# ESP32-S3 register map
Vendor: ESPRESSIF SYSTEMS (SHANGHAI) CO., LTD.; Series: ESP32 S-Series; File version: 22
CPU: Xtensa LX7 r0p0, little endian, no MPU, FPU, 0 interrupt priority bits
Address unit: 32 bits
Registers are 32-bit, read-write, reset 0x0 unless marked. A register's access mark holds for its fields unless they carry their own. Offsets are from the block's base; [hi:lo] are bit positions.

## UART0 — UART (Universal Asynchronous Receiver-Transmitter) Controller 0
Base 0x60000000
Same registers: UART1 0x60010000, UART2 0x6002E000
0x00 FIFO ro — FIFO data register
  [7:0] RXFIFO_RD_BYTE — UART 0 accesses FIFO via this register.
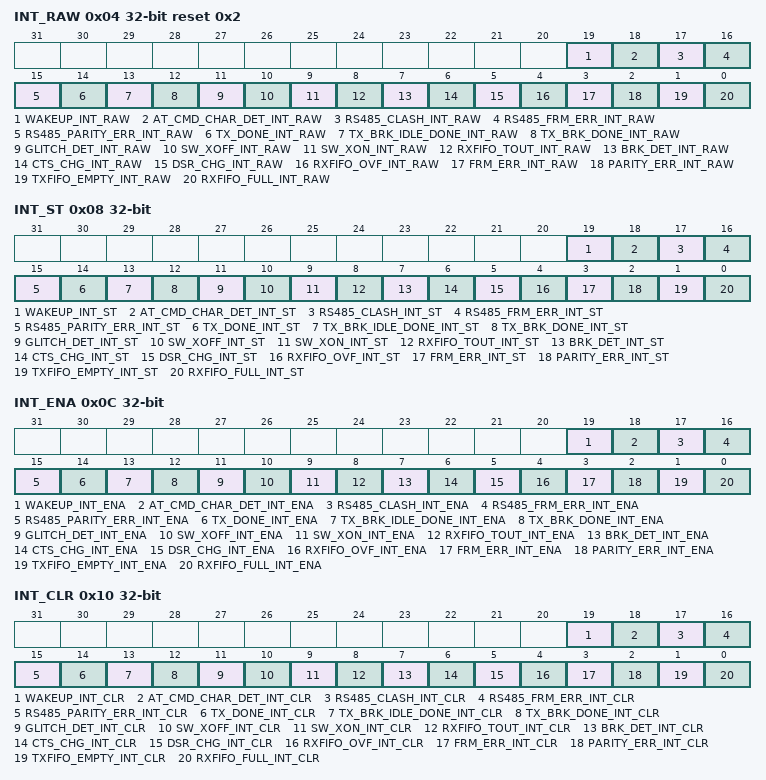
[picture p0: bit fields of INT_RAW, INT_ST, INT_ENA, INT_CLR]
0x04 INT_RAW reset 0x2 — Raw interrupt status
  [19] WAKEUP_INT_RAW — This interrupt raw bit turns to high level when input rxd edge changes more times than what reg_active_threshold specifies in light sleeping mode.
  [18] AT_CMD_CHAR_DET_INT_RAW — This interrupt raw bit turns to high level when receiver detects the configured at_cmd char.
  [17] RS485_CLASH_INT_RAW — This interrupt raw bit turns to high level when detects a clash between transmitter and receiver in rs485 mode.
  [16] RS485_FRM_ERR_INT_RAW — This interrupt raw bit turns to high level when receiver detects a data frame error from the echo of transmitter in rs485 mode.
  [15] RS485_PARITY_ERR_INT_RAW — This interrupt raw bit turns to high level when receiver detects a parity error from the echo of transmitter in rs485 mode.
  [14] TX_DONE_INT_RAW — This interrupt raw bit turns to high level when transmitter has send out all data in FIFO.
  [13] TX_BRK_IDLE_DONE_INT_RAW — This interrupt raw bit turns to high level when transmitter has kept the shortest duration after sending the last data.
  [12] TX_BRK_DONE_INT_RAW — This interrupt raw bit turns to high level when transmitter completes sending NULL characters, after all data in Tx-FIFO are sent.
  [11] GLITCH_DET_INT_RAW — This interrupt raw bit turns to high level when receiver detects a glitch in the middle of a start bit.
  [10] SW_XOFF_INT_RAW — This interrupt raw bit turns to high level when receiver receives Xoff char when uart_sw_flow_con_en is set to 1.
  [9] SW_XON_INT_RAW — This interrupt raw bit turns to high level when receiver recevies Xon char when uart_sw_flow_con_en is set to 1.
  [8] RXFIFO_TOUT_INT_RAW — This interrupt raw bit turns to high level when receiver takes more time than rx_tout_thrhd to receive a byte.
  [7] BRK_DET_INT_RAW — This interrupt raw bit turns to high level when receiver detects a 0 after the stop bit.
  [6] CTS_CHG_INT_RAW — This interrupt raw bit turns to high level when receiver detects the edge change of CTSn signal.
  [5] DSR_CHG_INT_RAW — This interrupt raw bit turns to high level when receiver detects the edge change of DSRn signal.
  [4] RXFIFO_OVF_INT_RAW — This interrupt raw bit turns to high level when receiver receives more data than the FIFO can store.
  [3] FRM_ERR_INT_RAW — This interrupt raw bit turns to high level when receiver detects a data frame error .
  [2] PARITY_ERR_INT_RAW — This interrupt raw bit turns to high level when receiver detects a parity error in the data.
  [1] TXFIFO_EMPTY_INT_RAW — This interrupt raw bit turns to high level when the amount of data in Tx-FIFO is less than what txfifo_empty_thrhd specifies .
  [0] RXFIFO_FULL_INT_RAW — This interrupt raw bit turns to high level when receiver receives more data than what rxfifo_full_thrhd specifies.
0x08 INT_ST ro — Masked interrupt status
  [19] WAKEUP_INT_ST — This is the status bit for uart_wakeup_int_raw when uart_wakeup_int_ena is set to 1.
  [18] AT_CMD_CHAR_DET_INT_ST — This is the status bit for at_cmd_det_int_raw when at_cmd_char_det_int_ena is set to 1.
  [17] RS485_CLASH_INT_ST — This is the status bit for rs485_clash_int_raw when rs485_clash_int_ena is set to 1.
  [16] RS485_FRM_ERR_INT_ST — This is the status bit for rs485_frm_err_int_raw when rs485_fm_err_int_ena is set to 1.
  [15] RS485_PARITY_ERR_INT_ST — This is the status bit for rs485_parity_err_int_raw when rs485_parity_int_ena is set to 1.
  [14] TX_DONE_INT_ST — This is the status bit for tx_done_int_raw when tx_done_int_ena is set to 1.
  [13] TX_BRK_IDLE_DONE_INT_ST — This is the stauts bit for tx_brk_idle_done_int_raw when tx_brk_idle_done_int_ena is set to 1.
  [12] TX_BRK_DONE_INT_ST — This is the status bit for tx_brk_done_int_raw when tx_brk_done_int_ena is set to 1.
  [11] GLITCH_DET_INT_ST — This is the status bit for glitch_det_int_raw when glitch_det_int_ena is set to 1.
  [10] SW_XOFF_INT_ST — This is the status bit for sw_xoff_int_raw when sw_xoff_int_ena is set to 1.
  [9] SW_XON_INT_ST — This is the status bit for sw_xon_int_raw when sw_xon_int_ena is set to 1.
  [8] RXFIFO_TOUT_INT_ST — This is the status bit for rxfifo_tout_int_raw when rxfifo_tout_int_ena is set to 1.
  [7] BRK_DET_INT_ST — This is the status bit for brk_det_int_raw when brk_det_int_ena is set to 1.
  [6] CTS_CHG_INT_ST — This is the status bit for cts_chg_int_raw when cts_chg_int_ena is set to 1.
  [5] DSR_CHG_INT_ST — This is the status bit for dsr_chg_int_raw when dsr_chg_int_ena is set to 1.
  [4] RXFIFO_OVF_INT_ST — This is the status bit for rxfifo_ovf_int_raw when rxfifo_ovf_int_ena is set to 1.
  [3] FRM_ERR_INT_ST — This is the status bit for frm_err_int_raw when frm_err_int_ena is set to 1.
  [2] PARITY_ERR_INT_ST — This is the status bit for parity_err_int_raw when parity_err_int_ena is set to 1.
  [1] TXFIFO_EMPTY_INT_ST — This is the status bit for txfifo_empty_int_raw when txfifo_empty_int_ena is set to 1.
  [0] RXFIFO_FULL_INT_ST — This is the status bit for rxfifo_full_int_raw when rxfifo_full_int_ena is set to 1.
0x0C INT_ENA — Interrupt enable bits
  [19] WAKEUP_INT_ENA — This is the enable bit for uart_wakeup_int_st register.
  [18] AT_CMD_CHAR_DET_INT_ENA — This is the enable bit for at_cmd_char_det_int_st register.
  [17] RS485_CLASH_INT_ENA — This is the enable bit for rs485_clash_int_st register.
  [16] RS485_FRM_ERR_INT_ENA — This is the enable bit for rs485_parity_err_int_st register.
  [15] RS485_PARITY_ERR_INT_ENA — This is the enable bit for rs485_parity_err_int_st register.
  [14] TX_DONE_INT_ENA — This is the enable bit for tx_done_int_st register.
  [13] TX_BRK_IDLE_DONE_INT_ENA — This is the enable bit for tx_brk_idle_done_int_st register.
  [12] TX_BRK_DONE_INT_ENA — This is the enable bit for tx_brk_done_int_st register.
  [11] GLITCH_DET_INT_ENA — This is the enable bit for glitch_det_int_st register.
  [10] SW_XOFF_INT_ENA — This is the enable bit for sw_xoff_int_st register.
  [9] SW_XON_INT_ENA — This is the enable bit for sw_xon_int_st register.
  [8] RXFIFO_TOUT_INT_ENA — This is the enable bit for rxfifo_tout_int_st register.
  [7] BRK_DET_INT_ENA — This is the enable bit for brk_det_int_st register.
  [6] CTS_CHG_INT_ENA — This is the enable bit for cts_chg_int_st register.
  [5] DSR_CHG_INT_ENA — This is the enable bit for dsr_chg_int_st register.
  [4] RXFIFO_OVF_INT_ENA — This is the enable bit for rxfifo_ovf_int_st register.
  [3] FRM_ERR_INT_ENA — This is the enable bit for frm_err_int_st register.
  [2] PARITY_ERR_INT_ENA — This is the enable bit for parity_err_int_st register.
  [1] TXFIFO_EMPTY_INT_ENA — This is the enable bit for txfifo_empty_int_st register.
  [0] RXFIFO_FULL_INT_ENA — This is the enable bit for rxfifo_full_int_st register.
0x10 INT_CLR wo — Interrupt clear bits
  [19] WAKEUP_INT_CLR — Set this bit to clear the uart_wakeup_int_raw interrupt.
  [18] AT_CMD_CHAR_DET_INT_CLR — Set this bit to clear the at_cmd_char_det_int_raw interrupt.
  [17] RS485_CLASH_INT_CLR — Set this bit to clear the rs485_clash_int_raw interrupt.
  [16] RS485_FRM_ERR_INT_CLR — Set this bit to clear the rs485_frm_err_int_raw interrupt.
  [15] RS485_PARITY_ERR_INT_CLR — Set this bit to clear the rs485_parity_err_int_raw interrupt.
  [14] TX_DONE_INT_CLR — Set this bit to clear the tx_done_int_raw interrupt.
  [13] TX_BRK_IDLE_DONE_INT_CLR — Set this bit to clear the tx_brk_idle_done_int_raw interrupt.
  [12] TX_BRK_DONE_INT_CLR — Set this bit to clear the tx_brk_done_int_raw interrupt..
  [11] GLITCH_DET_INT_CLR — Set this bit to clear the glitch_det_int_raw interrupt.
  [10] SW_XOFF_INT_CLR — Set this bit to clear the sw_xoff_int_raw interrupt.
  [9] SW_XON_INT_CLR — Set this bit to clear the sw_xon_int_raw interrupt.
  [8] RXFIFO_TOUT_INT_CLR — Set this bit to clear the rxfifo_tout_int_raw interrupt.
  [7] BRK_DET_INT_CLR — Set this bit to clear the brk_det_int_raw interrupt.
  [6] CTS_CHG_INT_CLR — Set this bit to clear the cts_chg_int_raw interrupt.
  [5] DSR_CHG_INT_CLR — Set this bit to clear the dsr_chg_int_raw interrupt.
  [4] RXFIFO_OVF_INT_CLR — Set this bit to clear rxfifo_ovf_int_raw interrupt.
  [3] FRM_ERR_INT_CLR — Set this bit to clear frm_err_int_raw interrupt.
  [2] PARITY_ERR_INT_CLR — Set this bit to clear parity_err_int_raw interrupt.
  [1] TXFIFO_EMPTY_INT_CLR — Set this bit to clear txfifo_empty_int_raw interrupt.
  [0] RXFIFO_FULL_INT_CLR — Set this bit to clear the rxfifo_full_int_raw interrupt.
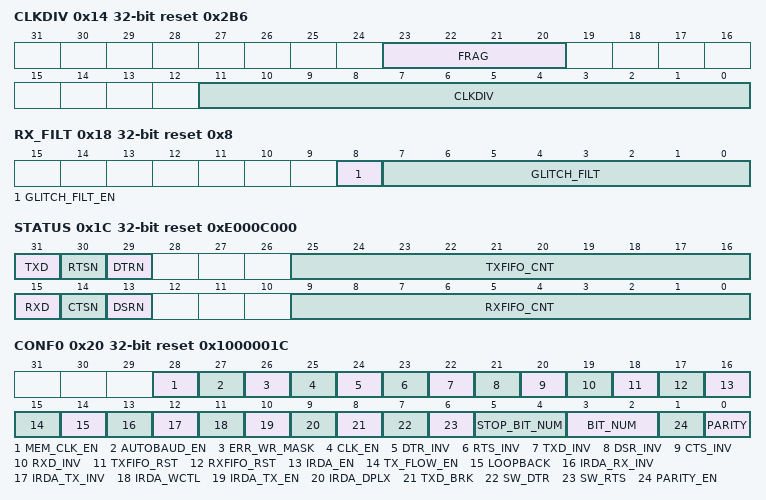
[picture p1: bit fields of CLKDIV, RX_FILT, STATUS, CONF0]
0x14 CLKDIV reset 0x2B6 — Clock divider configuration
  [23:20] FRAG — The decimal part of the frequency divider factor.
  [11:0] CLKDIV — The integral part of the frequency divider factor.
0x18 RX_FILT reset 0x8 — Rx Filter configuration
  [8] GLITCH_FILT_EN — Set this bit to enable Rx signal filter.
  [7:0] GLITCH_FILT — when input pulse width is lower than this value, the pulse is ignored.
0x1C STATUS ro reset 0xE000C000 — UART status register
  [31] TXD — This bit represents the level of the internal uart txd signal.
  [30] RTSN — This bit represents the level of the internal uart rts signal.
  [29] DTRN — This bit represents the level of the internal uart dtr signal.
  [25:16] TXFIFO_CNT — Stores the byte number of data in Tx-FIFO.
  [15] RXD — This register represent the level value of the internal uart rxd signal.
  [14] CTSN — This register represent the level value of the internal uart cts signal.
  [13] DSRN — The register represent the level value of the internal uart dsr signal.
  [9:0] RXFIFO_CNT — Stores the byte number of valid data in Rx-FIFO.
0x20 CONF0 reset 0x1000001C — a
  [28] MEM_CLK_EN — UART memory clock gate enable signal.
  [27] AUTOBAUD_EN — This is the enable bit for detecting baudrate.
  [26] ERR_WR_MASK — 1'h1: Receiver stops storing data into FIFO when data is wrong. 1'h0: Receiver stores the data even if the received data is wrong.
  [25] CLK_EN — 1'h1: Force clock on for register. 1'h0: Support clock only when application writes registers.
  [24] DTR_INV — Set this bit to inverse the level value of uart dtr signal.
  [23] RTS_INV — Set this bit to inverse the level value of uart rts signal.
  [22] TXD_INV — Set this bit to inverse the level value of uart txd signal.
  [21] DSR_INV — Set this bit to inverse the level value of uart dsr signal.
  [20] CTS_INV — Set this bit to inverse the level value of uart cts signal.
  [19] RXD_INV — Set this bit to inverse the level value of uart rxd signal.
  [18] TXFIFO_RST — Set this bit to reset the uart transmit-FIFO.
  [17] RXFIFO_RST — Set this bit to reset the uart receive-FIFO.
  [16] IRDA_EN — Set this bit to enable IrDA protocol.
  [15] TX_FLOW_EN — Set this bit to enable flow control function for transmitter.
  [14] LOOPBACK — Set this bit to enable uart loopback test mode.
  [13] IRDA_RX_INV — Set this bit to invert the level of IrDA receiver.
  [12] IRDA_TX_INV — Set this bit to invert the level of IrDA transmitter.
  [11] IRDA_WCTL — 1'h1: The IrDA transmitter's 11th bit is the same as 10th bit. 1'h0: Set IrDA transmitter's 11th bit to 0.
  [10] IRDA_TX_EN — This is the start enable bit for IrDA transmitter.
  [9] IRDA_DPLX — Set this bit to enable IrDA loopback mode.
  [8] TXD_BRK — Set this bit to enbale transmitter to send NULL when the process of sending data is done.
  [7] SW_DTR — This register is used to configure the software dtr signal which is used in software flow control.
  [6] SW_RTS — This register is used to configure the software rts signal which is used in software flow control.
  [5:4] STOP_BIT_NUM — This register is used to set the length of stop bit.
  [3:2] BIT_NUM — This register is used to set the length of data.
  [1] PARITY_EN — Set this bit to enable uart parity check.
  [0] PARITY — This register is used to configure the parity check mode.
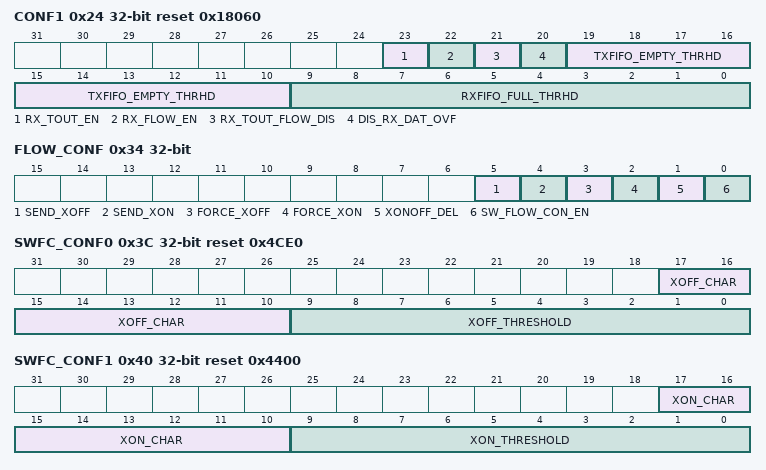
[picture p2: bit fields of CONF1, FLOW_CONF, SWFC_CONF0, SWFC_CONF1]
0x24 CONF1 reset 0x18060 — Configuration register 1
  [23] RX_TOUT_EN — This is the enble bit for uart receiver's timeout function.
  [22] RX_FLOW_EN — This is the flow enable bit for UART receiver.
  [21] RX_TOUT_FLOW_DIS — Set this bit to stop accumulating idle_cnt when hardware flow control works.
  [20] DIS_RX_DAT_OVF — Disable UART Rx data overflow detect.
  [19:10] TXFIFO_EMPTY_THRHD — It will produce txfifo_empty_int interrupt when the data amount in Tx-FIFO is less than this register value.
  [9:0] RXFIFO_FULL_THRHD — It will produce rxfifo_full_int interrupt when receiver receives more data than this register value.
0x28 LOWPULSE ro reset 0xFFF — Autobaud minimum low pulse duration register
  [11:0] MIN_CNT — This register stores the value of the minimum duration time of the low level pulse. It is used in baud rate-detect process.
0x2C HIGHPULSE ro reset 0xFFF — Autobaud minimum high pulse duration register
  [11:0] MIN_CNT — This register stores the value of the maxinum duration time for the high level pulse. It is used in baud rate-detect process.
0x30 RXD_CNT ro — Autobaud edge change count register
  [9:0] RXD_EDGE_CNT — This register stores the count of rxd edge change. It is used in baud rate-detect process.
0x34 FLOW_CONF — Software flow-control configuration
  [5] SEND_XOFF — Set this bit to send Xoff char. It is cleared by hardware automatically.
  [4] SEND_XON — Set this bit to send Xon char. It is cleared by hardware automatically.
  [3] FORCE_XOFF — Set this bit to stop the transmitter from sending data.
  [2] FORCE_XON — Set this bit to enable the transmitter to go on sending data.
  [1] XONOFF_DEL — Set this bit to remove flow control char from the received data.
  [0] SW_FLOW_CON_EN — Set this bit to enable software flow control. It is used with register sw_xon or sw_xoff.
0x38 SLEEP_CONF reset 0xF0 — Sleep-mode configuration
  [9:0] ACTIVE_THRESHOLD — The uart is activated from light sleeping mode when the input rxd edge changes more times than this register value.
0x3C SWFC_CONF0 reset 0x4CE0 — Software flow-control character configuration
  [17:10] XOFF_CHAR — This register stores the Xoff flow control char.
  [9:0] XOFF_THRESHOLD — When the data amount in Rx-FIFO is more than this register value with uart_sw_flow_con_en set to 1, it will send a Xoff char.
0x40 SWFC_CONF1 reset 0x4400 — Software flow-control character configuration
  [17:10] XON_CHAR — This register stores the Xon flow control char.
  [9:0] XON_THRESHOLD — When the data amount in Rx-FIFO is less than this register value with uart_sw_flow_con_en set to 1, it will send a Xon char.
0x44 TXBRK_CONF reset 0xA — Tx Break character configuration
  [7:0] TX_BRK_NUM — This register is used to configure the number of 0 to be sent after the process of sending data is done. It is active when txd_brk is set to 1.
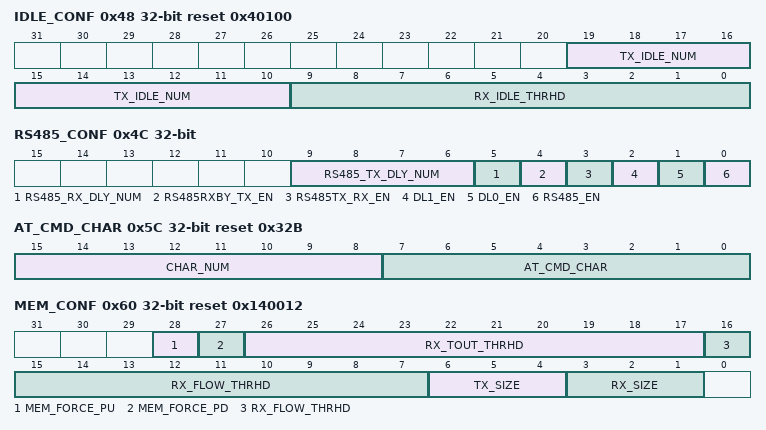
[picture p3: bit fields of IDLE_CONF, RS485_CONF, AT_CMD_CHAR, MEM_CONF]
0x48 IDLE_CONF reset 0x40100 — Frame-end idle configuration
  [19:10] TX_IDLE_NUM — This register is used to configure the duration time between transfers.
  [9:0] RX_IDLE_THRHD — It will produce frame end signal when receiver takes more time to receive one byte data than this register value.
0x4C RS485_CONF — RS485 mode configuration
  [9:6] RS485_TX_DLY_NUM — This register is used to delay the transmitter's internal data signal.
  [5] RS485_RX_DLY_NUM — This register is used to delay the receiver's internal data signal.
  [4] RS485RXBY_TX_EN — 1'h1: enable rs485 transmitter to send data when rs485 receiver line is busy.
  [3] RS485TX_RX_EN — Set this bit to enable receiver could receive data when the transmitter is transmitting data in rs485 mode.
  [2] DL1_EN — Set this bit to delay the stop bit by 1 bit.
  [1] DL0_EN — Set this bit to delay the stop bit by 1 bit.
  [0] RS485_EN — Set this bit to choose the rs485 mode.
0x50 AT_CMD_PRECNT reset 0x901 — Pre-sequence timing configuration
  [15:0] PRE_IDLE_NUM — This register is used to configure the idle duration time before the first at_cmd is received by receiver.
0x54 AT_CMD_POSTCNT reset 0x901 — Post-sequence timing configuration
  [15:0] POST_IDLE_NUM — This register is used to configure the duration time between the last at_cmd and the next data.
0x58 AT_CMD_GAPTOUT reset 0xB — Timeout configuration
  [15:0] RX_GAP_TOUT — This register is used to configure the duration time between the at_cmd chars.
0x5C AT_CMD_CHAR reset 0x32B — AT escape sequence detection configuration
  [15:8] CHAR_NUM — This register is used to configure the num of continuous at_cmd chars received by receiver.
  [7:0] AT_CMD_CHAR — This register is used to configure the content of at_cmd char.
0x60 MEM_CONF reset 0x140012 — UART threshold and allocation configuration
  [28] MEM_FORCE_PU — Set this bit to force power up UART memory.
  [27] MEM_FORCE_PD — Set this bit to force power down UART memory.
  [26:17] RX_TOUT_THRHD — This register is used to configure the threshold time that receiver takes to receive one byte. The rxfifo_tout_int interrupt will be trigger when the receiver takes more time to receive one byte with rx_tout_en set to 1.
  [16:7] RX_FLOW_THRHD — This register is used to configure the maximum amount of data that can be received when hardware flow control works.
  [6:4] TX_SIZE — This register is used to configure the amount of mem allocated for transmit-FIFO. The default number is 128 bytes.
  [3:1] RX_SIZE — This register is used to configure the amount of mem allocated for receive-FIFO. The default number is 128 bytes.
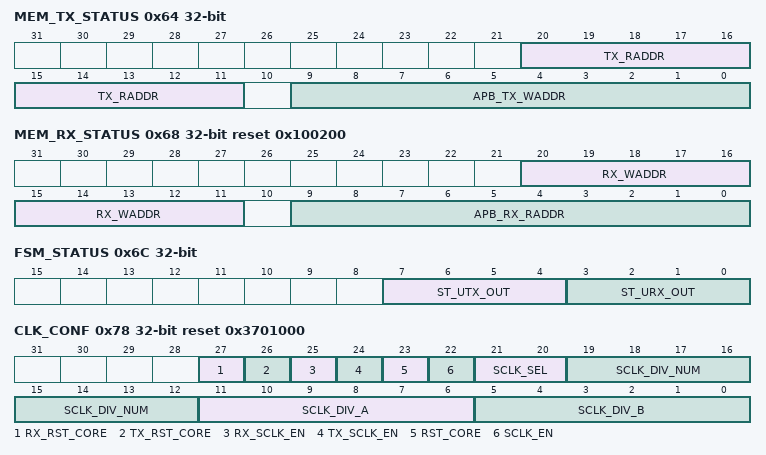
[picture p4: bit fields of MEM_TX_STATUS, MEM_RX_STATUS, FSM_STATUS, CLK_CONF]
0x64 MEM_TX_STATUS ro — Tx-FIFO write and read offset address.
  [20:11] TX_RADDR — This register stores the offset address in Tx-FIFO when Tx-FSM reads data via Tx-FIFO_Ctrl.
  [9:0] APB_TX_WADDR — This register stores the offset address in Tx-FIFO when software writes Tx-FIFO via APB.
0x68 MEM_RX_STATUS ro reset 0x100200 — Rx-FIFO write and read offset address.
  [20:11] RX_WADDR — This register stores the offset address in Rx-FIFO when Rx-FIFO_Ctrl writes Rx-FIFO. UART0 is 10'h200. UART1 is 10'h280. UART2 is 10'h300.
  [9:0] APB_RX_RADDR — This register stores the offset address in RX-FIFO when software reads data from Rx-FIFO via APB. UART0 is 10'h200. UART1 is 10'h280. UART2 is 10'h300.
0x6C FSM_STATUS ro — UART transmit and receive status.
  [7:4] ST_UTX_OUT — This is the status register of transmitter.
  [3:0] ST_URX_OUT — This is the status register of receiver.
0x70 POSPULSE ro reset 0xFFF — Autobaud high pulse register
  [11:0] POSEDGE_MIN_CNT — This register stores the minimal input clock count between two positive edges. It is used in boudrate-detect process.
0x74 NEGPULSE ro reset 0xFFF — Autobaud low pulse register
  [11:0] NEGEDGE_MIN_CNT — This register stores the minimal input clock count between two negative edges. It is used in boudrate-detect process.
0x78 CLK_CONF reset 0x3701000 — UART core clock configuration
  [27] RX_RST_CORE — Write 1 then write 0 to this bit, reset UART Rx.
  [26] TX_RST_CORE — Write 1 then write 0 to this bit, reset UART Tx.
  [25] RX_SCLK_EN — Set this bit to enable UART Rx clock.
  [24] TX_SCLK_EN — Set this bit to enable UART Tx clock.
  [23] RST_CORE — Write 1 then write 0 to this bit, reset UART Tx/Rx.
  [22] SCLK_EN — Set this bit to enable UART Tx/Rx clock.
  [21:20] SCLK_SEL — UART clock source select. 1: 80Mhz, 2: 8Mhz, 3: XTAL.
  [19:12] SCLK_DIV_NUM — The integral part of the frequency divider factor.
  [11:6] SCLK_DIV_A — The numerator of the frequency divider factor.
  [5:0] SCLK_DIV_B — The denominator of the frequency divider factor.
0x7C DATE reset 0x2008270 — UART Version register
  [31:0] DATE — This is the version register.
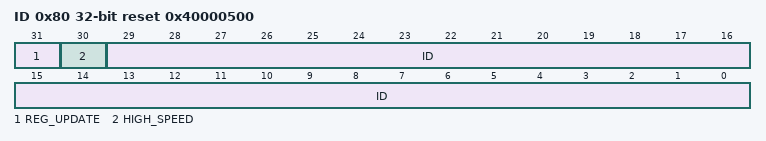
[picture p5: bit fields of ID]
0x80 ID reset 0x40000500 — UART ID register
  [31] REG_UPDATE — Software write 1 would synchronize registers into UART Core clock domain and would be cleared by hardware after synchronization is done.
  [30] HIGH_SPEED — This bit used to select synchronize mode. 1: Registers are auto synchronized into UART Core clock and UART core should be keep the same with APB clock. 0: After configure registers, software needs to write 1 to UART_REG_UPDATE to synchronize registers.
  [29:0] ID — This register is used to configure the uart_id.
